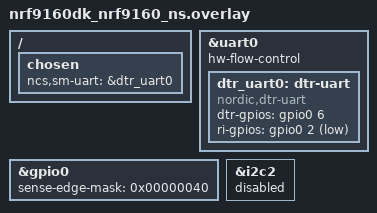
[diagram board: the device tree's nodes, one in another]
/*
 * Copyright (c) 2021 Nordic Semiconductor ASA
 *
 * SPDX-License-Identifier: LicenseRef-Nordic-5-Clause
 */

/ {
	chosen {
		ncs,sm-uart = &dtr_uart0;
	};
};

/* DTR with DK */
&uart0 {
	status = "okay";
	hw-flow-control;

	dtr_uart0: dtr-uart {
		compatible = "nordic,dtr-uart";
		dtr-gpios = <&gpio0 6 (GPIO_PULL_UP | GPIO_ACTIVE_HIGH)>; /* button0 */
		ri-gpios = <&gpio0 2 GPIO_ACTIVE_LOW>; /* led0 */
		status = "okay";
	};
};

&gpio0 {
	status = "okay";
	/* Use PORT event for DTR (6) pin to save power */
	sense-edge-mask = <0x00000040>;
};

&i2c2 {
	status = "disabled";
};
